VERSION ""

NS_ :

BS_:

BU_:

BO_ 3221225472 VECTOR__INDEPENDENT_SIG_MSG: 0 Vector__XXX
 SG_ Error_BMS_ID : 0|16@1+ (1,0) [0|0] "" Vector__XXX

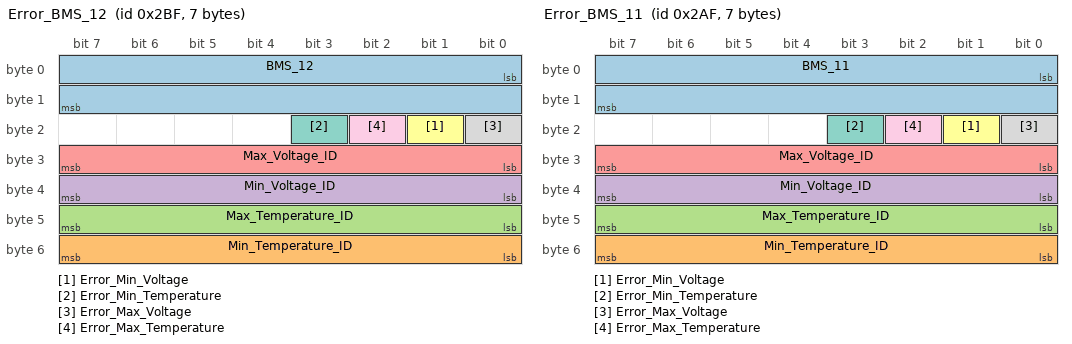
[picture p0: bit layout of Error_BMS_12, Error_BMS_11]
BO_ 703 Error_BMS_12: 7 Vector__XXX
 SG_ BMS_12 : 0|16@1- (1,0) [0|0] "" Vector__XXX
 SG_ Min_Temperature_ID : 48|8@1+ (1,0) [0|255] "" Vector__XXX
 SG_ Max_Temperature_ID : 40|8@1+ (1,0) [0|255] "" Vector__XXX
 SG_ Min_Voltage_ID : 32|8@1+ (1,0) [0|255] "" Vector__XXX
 SG_ Max_Voltage_ID : 24|8@1+ (1,0) [0|255] "" Vector__XXX
 SG_ Error_Min_Voltage : 17|1@1+ (1,0) [0|1] "" Vector__XXX
 SG_ Error_Min_Temperature : 19|1@1+ (1,0) [0|1] "" Vector__XXX
 SG_ Error_Max_Voltage : 16|1@1+ (1,0) [0|1] "" Vector__XXX
 SG_ Error_Max_Temperature : 18|1@1+ (1,0) [0|1] "" Vector__XXX

BO_ 687 Error_BMS_11: 7 Vector__XXX
 SG_ BMS_11 : 0|16@1- (1,0) [0|0] "" Vector__XXX
 SG_ Min_Temperature_ID : 48|8@1+ (1,0) [0|255] "" Vector__XXX
 SG_ Max_Temperature_ID : 40|8@1+ (1,0) [0|255] "" Vector__XXX
 SG_ Min_Voltage_ID : 32|8@1+ (1,0) [0|255] "" Vector__XXX
 SG_ Max_Voltage_ID : 24|8@1+ (1,0) [0|255] "" Vector__XXX
 SG_ Error_Min_Voltage : 17|1@1+ (1,0) [0|1] "" Vector__XXX
 SG_ Error_Min_Temperature : 19|1@1+ (1,0) [0|1] "" Vector__XXX
 SG_ Error_Max_Voltage : 16|1@1+ (1,0) [0|1] "" Vector__XXX
 SG_ Error_Max_Temperature : 18|1@1+ (1,0) [0|1] "" Vector__XXX

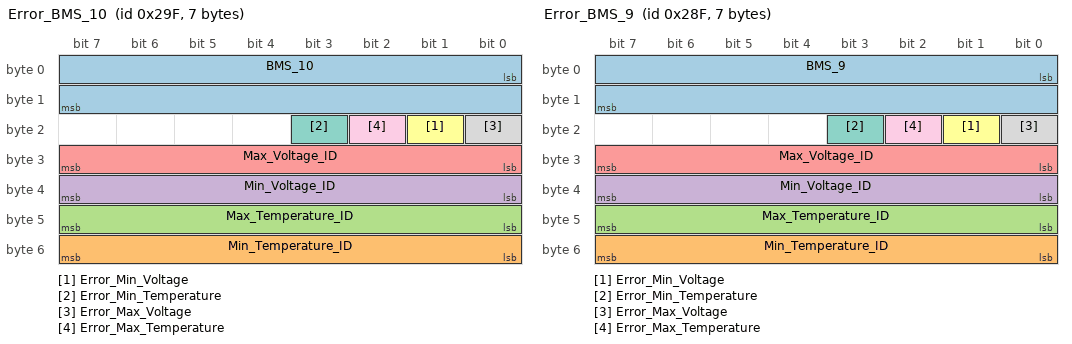
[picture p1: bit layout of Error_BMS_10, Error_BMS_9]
BO_ 671 Error_BMS_10: 7 Vector__XXX
 SG_ BMS_10 : 0|16@1- (1,0) [0|0] "" Vector__XXX
 SG_ Min_Temperature_ID : 48|8@1+ (1,0) [0|255] "" Vector__XXX
 SG_ Max_Temperature_ID : 40|8@1+ (1,0) [0|255] "" Vector__XXX
 SG_ Min_Voltage_ID : 32|8@1+ (1,0) [0|255] "" Vector__XXX
 SG_ Max_Voltage_ID : 24|8@1+ (1,0) [0|255] "" Vector__XXX
 SG_ Error_Min_Voltage : 17|1@1+ (1,0) [0|1] "" Vector__XXX
 SG_ Error_Min_Temperature : 19|1@1+ (1,0) [0|1] "" Vector__XXX
 SG_ Error_Max_Voltage : 16|1@1+ (1,0) [0|1] "" Vector__XXX
 SG_ Error_Max_Temperature : 18|1@1+ (1,0) [0|1] "" Vector__XXX

BO_ 655 Error_BMS_9: 7 Vector__XXX
 SG_ BMS_9 : 0|16@1- (1,0) [0|0] "" Vector__XXX
 SG_ Min_Temperature_ID : 48|8@1+ (1,0) [0|255] "" Vector__XXX
 SG_ Max_Temperature_ID : 40|8@1+ (1,0) [0|255] "" Vector__XXX
 SG_ Min_Voltage_ID : 32|8@1+ (1,0) [0|255] "" Vector__XXX
 SG_ Max_Voltage_ID : 24|8@1+ (1,0) [0|255] "" Vector__XXX
 SG_ Error_Min_Voltage : 17|1@1+ (1,0) [0|1] "" Vector__XXX
 SG_ Error_Min_Temperature : 19|1@1+ (1,0) [0|1] "" Vector__XXX
 SG_ Error_Max_Voltage : 16|1@1+ (1,0) [0|1] "" Vector__XXX
 SG_ Error_Max_Temperature : 18|1@1+ (1,0) [0|1] "" Vector__XXX

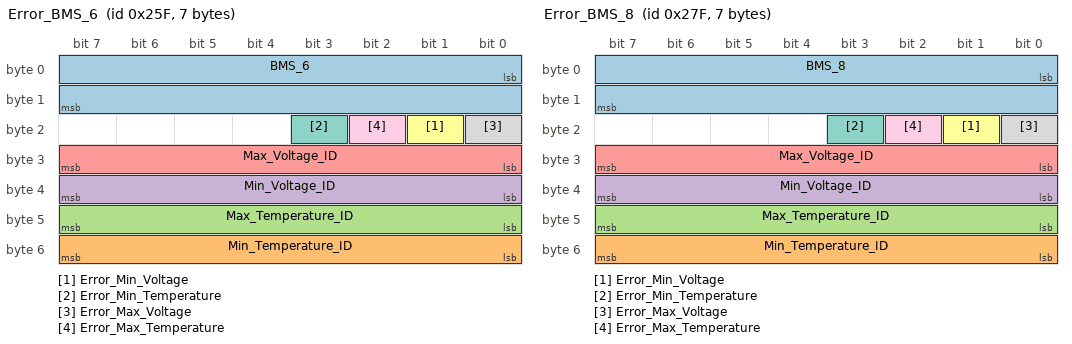
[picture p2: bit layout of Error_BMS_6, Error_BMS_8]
BO_ 607 Error_BMS_6: 7 Vector__XXX
 SG_ BMS_6 : 0|16@1- (1,0) [0|0] "" Vector__XXX
 SG_ Min_Temperature_ID : 48|8@1+ (1,0) [0|255] "" Vector__XXX
 SG_ Max_Temperature_ID : 40|8@1+ (1,0) [0|255] "" Vector__XXX
 SG_ Min_Voltage_ID : 32|8@1+ (1,0) [0|255] "" Vector__XXX
 SG_ Max_Voltage_ID : 24|8@1+ (1,0) [0|255] "" Vector__XXX
 SG_ Error_Min_Voltage : 17|1@1+ (1,0) [0|1] "" Vector__XXX
 SG_ Error_Min_Temperature : 19|1@1+ (1,0) [0|1] "" Vector__XXX
 SG_ Error_Max_Voltage : 16|1@1+ (1,0) [0|1] "" Vector__XXX
 SG_ Error_Max_Temperature : 18|1@1+ (1,0) [0|1] "" Vector__XXX

BO_ 639 Error_BMS_8: 7 Vector__XXX
 SG_ BMS_8 : 0|16@1- (1,0) [0|0] "" Vector__XXX
 SG_ Min_Temperature_ID : 48|8@1+ (1,0) [0|255] "" Vector__XXX
 SG_ Max_Temperature_ID : 40|8@1+ (1,0) [0|255] "" Vector__XXX
 SG_ Min_Voltage_ID : 32|8@1+ (1,0) [0|255] "" Vector__XXX
 SG_ Max_Voltage_ID : 24|8@1+ (1,0) [0|255] "" Vector__XXX
 SG_ Error_Min_Voltage : 17|1@1+ (1,0) [0|1] "" Vector__XXX
 SG_ Error_Min_Temperature : 19|1@1+ (1,0) [0|1] "" Vector__XXX
 SG_ Error_Max_Voltage : 16|1@1+ (1,0) [0|1] "" Vector__XXX
 SG_ Error_Max_Temperature : 18|1@1+ (1,0) [0|1] "" Vector__XXX

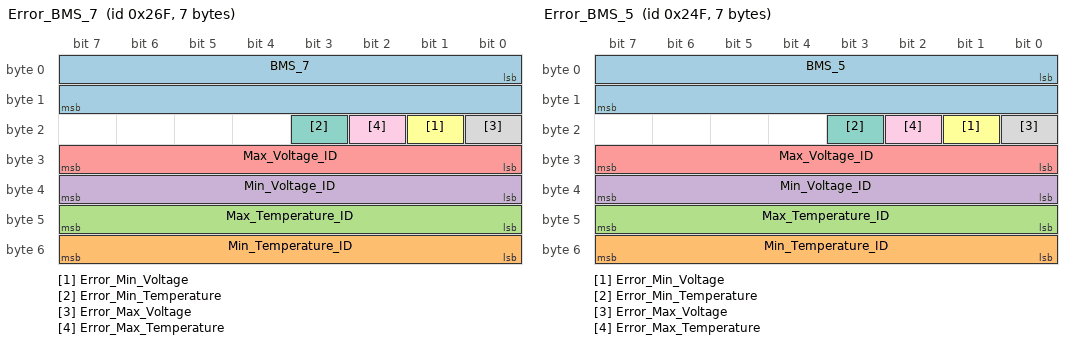
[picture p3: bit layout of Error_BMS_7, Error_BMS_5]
BO_ 623 Error_BMS_7: 7 Vector__XXX
 SG_ BMS_7 : 0|16@1- (1,0) [0|0] "" Vector__XXX
 SG_ Min_Temperature_ID : 48|8@1+ (1,0) [0|255] "" Vector__XXX
 SG_ Max_Temperature_ID : 40|8@1+ (1,0) [0|255] "" Vector__XXX
 SG_ Min_Voltage_ID : 32|8@1+ (1,0) [0|255] "" Vector__XXX
 SG_ Max_Voltage_ID : 24|8@1+ (1,0) [0|255] "" Vector__XXX
 SG_ Error_Min_Voltage : 17|1@1+ (1,0) [0|1] "" Vector__XXX
 SG_ Error_Min_Temperature : 19|1@1+ (1,0) [0|1] "" Vector__XXX
 SG_ Error_Max_Voltage : 16|1@1+ (1,0) [0|1] "" Vector__XXX
 SG_ Error_Max_Temperature : 18|1@1+ (1,0) [0|1] "" Vector__XXX

BO_ 591 Error_BMS_5: 7 Vector__XXX
 SG_ BMS_5 : 0|16@1- (1,0) [0|0] "" Vector__XXX
 SG_ Min_Temperature_ID : 48|8@1+ (1,0) [0|255] "" Vector__XXX
 SG_ Max_Temperature_ID : 40|8@1+ (1,0) [0|255] "" Vector__XXX
 SG_ Min_Voltage_ID : 32|8@1+ (1,0) [0|255] "" Vector__XXX
 SG_ Max_Voltage_ID : 24|8@1+ (1,0) [0|255] "" Vector__XXX
 SG_ Error_Min_Voltage : 17|1@1+ (1,0) [0|1] "" Vector__XXX
 SG_ Error_Min_Temperature : 19|1@1+ (1,0) [0|1] "" Vector__XXX
 SG_ Error_Max_Voltage : 16|1@1+ (1,0) [0|1] "" Vector__XXX
 SG_ Error_Max_Temperature : 18|1@1+ (1,0) [0|1] "" Vector__XXX

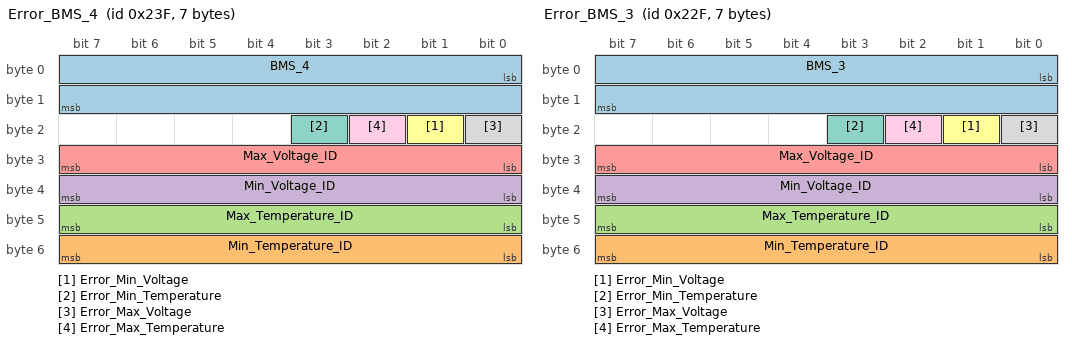
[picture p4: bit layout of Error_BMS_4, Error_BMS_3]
BO_ 575 Error_BMS_4: 7 Vector__XXX
 SG_ BMS_4 : 0|16@1- (1,0) [0|0] "" Vector__XXX
 SG_ Min_Temperature_ID : 48|8@1+ (1,0) [0|255] "" Vector__XXX
 SG_ Max_Temperature_ID : 40|8@1+ (1,0) [0|255] "" Vector__XXX
 SG_ Min_Voltage_ID : 32|8@1+ (1,0) [0|255] "" Vector__XXX
 SG_ Max_Voltage_ID : 24|8@1+ (1,0) [0|255] "" Vector__XXX
 SG_ Error_Min_Voltage : 17|1@1+ (1,0) [0|1] "" Vector__XXX
 SG_ Error_Min_Temperature : 19|1@1+ (1,0) [0|1] "" Vector__XXX
 SG_ Error_Max_Voltage : 16|1@1+ (1,0) [0|1] "" Vector__XXX
 SG_ Error_Max_Temperature : 18|1@1+ (1,0) [0|1] "" Vector__XXX

BO_ 559 Error_BMS_3: 7 Vector__XXX
 SG_ BMS_3 : 0|16@1- (1,0) [0|0] "" Vector__XXX
 SG_ Min_Temperature_ID : 48|8@1+ (1,0) [0|255] "" Vector__XXX
 SG_ Max_Temperature_ID : 40|8@1+ (1,0) [0|255] "" Vector__XXX
 SG_ Min_Voltage_ID : 32|8@1+ (1,0) [0|255] "" Vector__XXX
 SG_ Max_Voltage_ID : 24|8@1+ (1,0) [0|255] "" Vector__XXX
 SG_ Error_Min_Voltage : 17|1@1+ (1,0) [0|1] "" Vector__XXX
 SG_ Error_Min_Temperature : 19|1@1+ (1,0) [0|1] "" Vector__XXX
 SG_ Error_Max_Voltage : 16|1@1+ (1,0) [0|1] "" Vector__XXX
 SG_ Error_Max_Temperature : 18|1@1+ (1,0) [0|1] "" Vector__XXX

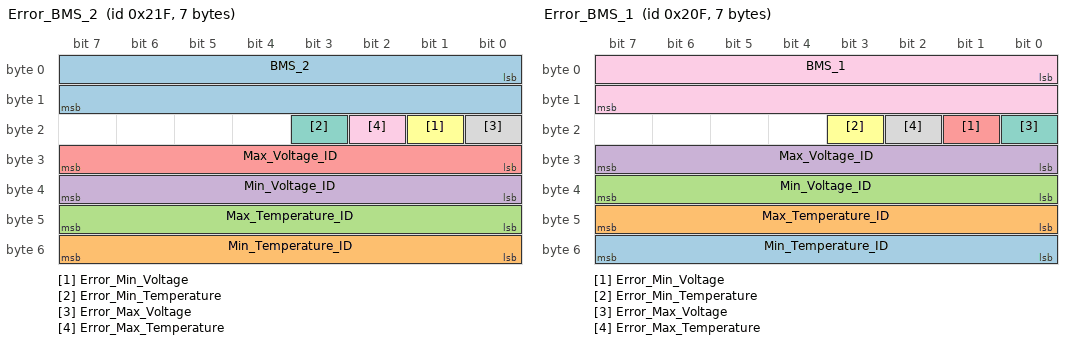
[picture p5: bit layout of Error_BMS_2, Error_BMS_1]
BO_ 543 Error_BMS_2: 7 Vector__XXX
 SG_ BMS_2 : 0|16@1- (1,0) [0|0] "" Vector__XXX
 SG_ Min_Temperature_ID : 48|8@1+ (1,0) [0|255] "" Vector__XXX
 SG_ Max_Temperature_ID : 40|8@1+ (1,0) [0|255] "" Vector__XXX
 SG_ Min_Voltage_ID : 32|8@1+ (1,0) [0|255] "" Vector__XXX
 SG_ Max_Voltage_ID : 24|8@1+ (1,0) [0|255] "" Vector__XXX
 SG_ Error_Min_Voltage : 17|1@1+ (1,0) [0|1] "" Vector__XXX
 SG_ Error_Min_Temperature : 19|1@1+ (1,0) [0|1] "" Vector__XXX
 SG_ Error_Max_Voltage : 16|1@1+ (1,0) [0|1] "" Vector__XXX
 SG_ Error_Max_Temperature : 18|1@1+ (1,0) [0|1] "" Vector__XXX

BO_ 527 Error_BMS_1: 7 Vector__XXX
 SG_ Min_Temperature_ID : 48|8@1+ (1,0) [0|255] "" Vector__XXX
 SG_ Max_Temperature_ID : 40|8@1+ (1,0) [0|255] "" Vector__XXX
 SG_ Min_Voltage_ID : 32|8@1+ (1,0) [0|255] "" Vector__XXX
 SG_ Max_Voltage_ID : 24|8@1+ (1,0) [0|255] "" Vector__XXX
 SG_ Error_Min_Voltage : 17|1@1+ (1,0) [0|1] "" Vector__XXX
 SG_ Error_Min_Temperature : 19|1@1+ (1,0) [0|1] "" Vector__XXX
 SG_ Error_Max_Voltage : 16|1@1+ (1,0) [0|1] "" Vector__XXX
 SG_ Error_Max_Temperature : 18|1@1+ (1,0) [0|1] "" Vector__XXX
 SG_ BMS_1 : 0|16@1- (1,0) [0|0] "" Vector__XXX

BO_ 256 Set_Min_Max_Voltage_Temp: 6 Vector__XXX
 SG_ Value_Min_Allowed_Voltage : 16|16@1+ (0.0001,0) [0|0] "V" Vector__XXX
 SG_ Value_Max_Allowed_Voltage : 0|16@1+ (0.0001,0) [0|0] "V" Vector__XXX
 SG_ Value_Max_Allowed_Temperature : 32|16@1- (0.01,0) [-327.68|327.67] "°C" Vector__XXX

BO_ 434 RX_BMS_12_Voltage_05_08: 0 Vector__XXX

BO_ 433 RX_BMS_12_Voltage_01_04: 0 Vector__XXX

BO_ 440 RX_BMS_12_Temp_05_REF: 0 Vector__XXX

BO_ 439 RX_BMS_12_Temp_01_04: 0 Vector__XXX

BO_ 438 RX_BMS_12_Extrem_Voltages: 0 Vector__XXX

BO_ 445 RX_BMS_12_Extrem_Temp: 0 Vector__XXX

BO_ 418 RX_BMS_11_Voltage_05_08: 0 Vector__XXX

BO_ 417 RX_BMS_11_Voltage_01_04: 0 Vector__XXX

BO_ 424 RX_BMS_11_Temp_05_REF: 0 Vector__XXX

BO_ 423 RX_BMS_11_Temp_01_04: 0 Vector__XXX

BO_ 422 RX_BMS_11_Extrem_Voltages: 0 Vector__XXX

BO_ 429 RX_BMS_11_Extrem_Temp: 0 Vector__XXX

BO_ 402 RX_BMS_10_Voltage_05_08: 0 Vector__XXX

BO_ 401 RX_BMS_10_Voltage_01_04: 0 Vector__XXX

BO_ 408 RX_BMS_10_Temp_05_REF: 0 Vector__XXX

BO_ 407 RX_BMS_10_Temp_01_04: 0 Vector__XXX

BO_ 406 RX_BMS_10_Extrem_Voltages: 0 Vector__XXX

BO_ 413 RX_BMS_10_Extrem_Temp: 0 Vector__XXX

BO_ 386 RX_BMS_9_Voltage_05_08: 0 Vector__XXX

BO_ 385 RX_BMS_9_Voltage_01_04: 0 Vector__XXX

BO_ 392 RX_BMS_9_Temp_05_REF: 0 Vector__XXX

BO_ 391 RX_BMS_9_Temp_01_04: 0 Vector__XXX

BO_ 390 RX_BMS_9_Extrem_Voltages: 0 Vector__XXX

BO_ 397 RX_BMS_9_Extrem_Temp: 0 Vector__XXX

BO_ 370 RX_BMS_8_Voltage_05_08: 0 Vector__XXX

BO_ 369 RX_BMS_8_Voltage_01_04: 0 Vector__XXX

BO_ 376 RX_BMS_8_Temp_05_REF: 0 Vector__XXX

BO_ 375 RX_BMS_8_Temp_01_04: 0 Vector__XXX

BO_ 374 RX_BMS_8_Extrem_Voltages: 0 Vector__XXX

BO_ 381 RX_BMS_8_Extrem_Temp: 0 Vector__XXX

BO_ 354 RX_BMS_7_Voltage_05_08: 0 Vector__XXX

BO_ 353 RX_BMS_7_Voltage_01_04: 0 Vector__XXX

BO_ 360 RX_BMS_7_Temp_05_REF: 0 Vector__XXX

BO_ 359 RX_BMS_7_Temp_01_04: 0 Vector__XXX

BO_ 358 RX_BMS_7_Extrem_Voltages: 0 Vector__XXX

BO_ 365 RX_BMS_7_Extrem_Temp: 0 Vector__XXX

BO_ 338 RX_BMS_6_Voltage_05_08: 0 Vector__XXX

BO_ 337 RX_BMS_6_Voltage_01_04: 0 Vector__XXX

BO_ 344 RX_BMS_6_Temp_05_REF: 0 Vector__XXX

BO_ 343 RX_BMS_6_Temp_01_04: 0 Vector__XXX

BO_ 342 RX_BMS_6_Extrem_Voltages: 0 Vector__XXX

BO_ 349 RX_BMS_6_Extrem_Temp: 0 Vector__XXX

BO_ 322 RX_BMS_5_Voltage_05_08: 0 Vector__XXX

BO_ 321 RX_BMS_5_Voltage_01_04: 0 Vector__XXX

BO_ 328 RX_BMS_5_Temp_05_REF: 0 Vector__XXX

BO_ 327 RX_BMS_5_Temp_01_04: 0 Vector__XXX

BO_ 326 RX_BMS_5_Extrem_Voltages: 0 Vector__XXX

BO_ 333 RX_BMS_5_Extrem_Temp: 0 Vector__XXX

BO_ 306 RX_BMS_4_Voltage_05_08: 0 Vector__XXX

BO_ 305 RX_BMS_4_Voltage_01_04: 0 Vector__XXX

BO_ 312 RX_BMS_4_Temp_05_REF: 0 Vector__XXX

BO_ 311 RX_BMS_4_Temp_01_04: 0 Vector__XXX

BO_ 310 RX_BMS_4_Extrem_Voltages: 0 Vector__XXX

BO_ 317 RX_BMS_4_Extrem_Temp: 0 Vector__XXX

BO_ 290 RX_BMS_3_Voltage_05_08: 0 Vector__XXX

BO_ 289 RX_BMS_3_Voltage_01_04: 0 Vector__XXX

BO_ 296 RX_BMS_3_Temp_05_REF: 0 Vector__XXX

BO_ 295 RX_BMS_3_Temp_01_04: 0 Vector__XXX

BO_ 294 RX_BMS_3_Extrem_Voltages: 0 Vector__XXX

BO_ 301 RX_BMS_3_Extrem_Temp: 0 Vector__XXX

BO_ 274 RX_BMS_2_Voltage_05_08: 0 Vector__XXX

BO_ 273 RX_BMS_2_Voltage_01_04: 0 Vector__XXX

BO_ 280 RX_BMS_2_Temp_05_REF: 0 Vector__XXX

BO_ 279 RX_BMS_2_Temp_01_04: 0 Vector__XXX

BO_ 278 RX_BMS_2_Extrem_Voltages: 0 Vector__XXX

BO_ 285 RX_BMS_2_Extrem_Temp: 0 Vector__XXX

BO_ 258 RX_BMS_1_Voltage_05_REF: 0 Vector__XXX

BO_ 257 RX_BMS_1_Voltage_01_04: 0 Vector__XXX

BO_ 264 RX_BMS_1_Temp_05_REF: 0 Vector__XXX

BO_ 263 RX_BMS_1_Temp_01_04: 0 Vector__XXX

BO_ 262 RX_BMS_1_Extrem_Voltages: 0 Vector__XXX

BO_ 269 RX_BMS_1_Extrem_Temp: 0 Vector__XXX

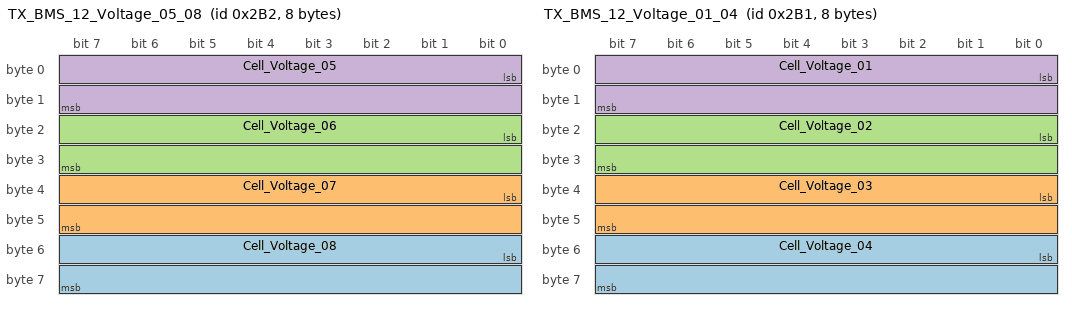
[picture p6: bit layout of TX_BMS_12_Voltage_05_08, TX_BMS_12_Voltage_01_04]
BO_ 690 TX_BMS_12_Voltage_05_08: 8 Vector__XXX
 SG_ Cell_Voltage_08 : 48|16@1+ (0.0001,0) [0|6.5535] "V" Vector__XXX
 SG_ Cell_Voltage_07 : 32|16@1+ (0.0001,0) [0|6.5535] "V" Vector__XXX
 SG_ Cell_Voltage_06 : 16|16@1+ (0.0001,0) [0|6.5535] "V" Vector__XXX
 SG_ Cell_Voltage_05 : 0|16@1+ (0.0001,0) [0|6.5535] "V" Vector__XXX

BO_ 689 TX_BMS_12_Voltage_01_04: 8 Vector__XXX
 SG_ Cell_Voltage_04 : 48|16@1+ (0.0001,0) [0|6.5535] "V" Vector__XXX
 SG_ Cell_Voltage_03 : 32|16@1+ (0.0001,0) [0|6.5535] "V" Vector__XXX
 SG_ Cell_Voltage_02 : 16|16@1+ (0.0001,0) [0|6.5535] "V" Vector__XXX
 SG_ Cell_Voltage_01 : 0|16@1+ (0.0001,0) [0|6.5535] "V" Vector__XXX

BO_ 696 TX_BMS_12_Temp_05_REF: 4 Vector__XXX
 SG_ Ref_Voltage : 16|16@1- (1,0) [0|0] "V" Vector__XXX
 SG_ Cell_Temperature_05 : 0|16@1- (0.01,0) [-327.68|327.67] "°C" Vector__XXX

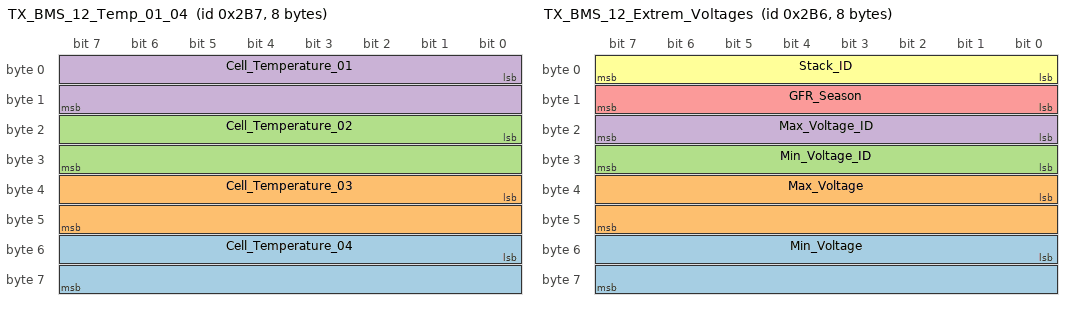
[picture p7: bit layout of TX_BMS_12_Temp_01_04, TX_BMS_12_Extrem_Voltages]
BO_ 695 TX_BMS_12_Temp_01_04: 8 Vector__XXX
 SG_ Cell_Temperature_04 : 48|16@1- (0.01,0) [-327.68|327.67] "°C" Vector__XXX
 SG_ Cell_Temperature_03 : 32|16@1- (0.01,0) [-327.68|327.67] "°C" Vector__XXX
 SG_ Cell_Temperature_02 : 16|16@1- (0.01,0) [-327.68|327.67] "°C" Vector__XXX
 SG_ Cell_Temperature_01 : 0|16@1- (0.01,0) [-327.68|327.67] "°C" Vector__XXX

BO_ 694 TX_BMS_12_Extrem_Voltages: 8 Vector__XXX
 SG_ Min_Voltage : 48|16@1+ (0.0001,0) [0|6.5535] "V" Vector__XXX
 SG_ Max_Voltage : 32|16@1+ (0.0001,0) [0|6.5535] "V" Vector__XXX
 SG_ Min_Voltage_ID : 24|8@1+ (1,0) [0|255] "" Vector__XXX
 SG_ Max_Voltage_ID : 16|8@1+ (1,0) [0|255] "" Vector__XXX
 SG_ GFR_Season : 8|8@1+ (1,0) [0|255] "" Vector__XXX
 SG_ Stack_ID : 0|8@1+ (1,0) [0|255] "" Vector__XXX

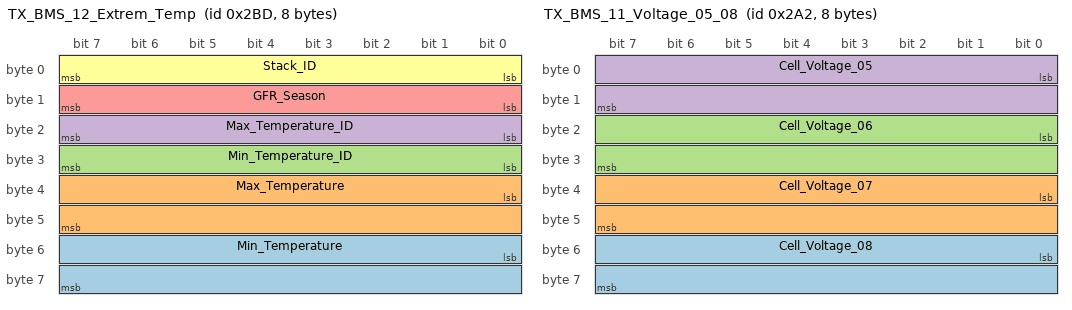
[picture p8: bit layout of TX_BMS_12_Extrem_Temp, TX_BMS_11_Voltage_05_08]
BO_ 701 TX_BMS_12_Extrem_Temp: 8 Vector__XXX
 SG_ Min_Temperature : 48|16@1- (0.01,0) [-327.68|327.67] "°C" Vector__XXX
 SG_ Max_Temperature : 32|16@1- (0.01,0) [-327.68|327.67] "°C" Vector__XXX
 SG_ Min_Temperature_ID : 24|8@1+ (1,0) [0|255] "" Vector__XXX
 SG_ Max_Temperature_ID : 16|8@1+ (1,0) [0|255] "" Vector__XXX
 SG_ GFR_Season : 8|8@1+ (1,0) [0|255] "" Vector__XXX
 SG_ Stack_ID : 0|8@1+ (1,0) [0|255] "" Vector__XXX

BO_ 674 TX_BMS_11_Voltage_05_08: 8 Vector__XXX
 SG_ Cell_Voltage_08 : 48|16@1+ (0.0001,0) [0|6.5535] "V" Vector__XXX
 SG_ Cell_Voltage_07 : 32|16@1+ (0.0001,0) [0|6.5535] "V" Vector__XXX
 SG_ Cell_Voltage_06 : 16|16@1+ (0.0001,0) [0|6.5535] "V" Vector__XXX
 SG_ Cell_Voltage_05 : 0|16@1+ (0.0001,0) [0|6.5535] "V" Vector__XXX

BO_ 673 TX_BMS_11_Voltage_01_04: 8 Vector__XXX
 SG_ Cell_Voltage_04 : 48|16@1+ (0.0001,0) [0|6.5535] "V" Vector__XXX
 SG_ Cell_Voltage_03 : 32|16@1+ (0.0001,0) [0|6.5535] "V" Vector__XXX
 SG_ Cell_Voltage_02 : 16|16@1+ (0.0001,0) [0|6.5535] "V" Vector__XXX
 SG_ Cell_Voltage_01 : 0|16@1+ (0.0001,0) [0|6.5535] "V" Vector__XXX

BO_ 680 TX_BMS_11_Temp_05_REF: 4 Vector__XXX
 SG_ Ref_Voltage : 16|16@1- (1,0) [0|0] "V" Vector__XXX
 SG_ Cell_Temperature_05 : 0|16@1- (0.01,0) [-327.68|327.67] "°C" Vector__XXX

BO_ 679 TX_BMS_11_Temp_01_04: 8 Vector__XXX
 SG_ Cell_Temperature_04 : 48|16@1- (0.01,0) [-327.68|327.67] "°C" Vector__XXX
 SG_ Cell_Temperature_03 : 32|16@1- (0.01,0) [-327.68|327.67] "°C" Vector__XXX
 SG_ Cell_Temperature_02 : 16|16@1- (0.01,0) [-327.68|327.67] "°C" Vector__XXX
 SG_ Cell_Temperature_01 : 0|16@1- (0.01,0) [-327.68|327.67] "°C" Vector__XXX

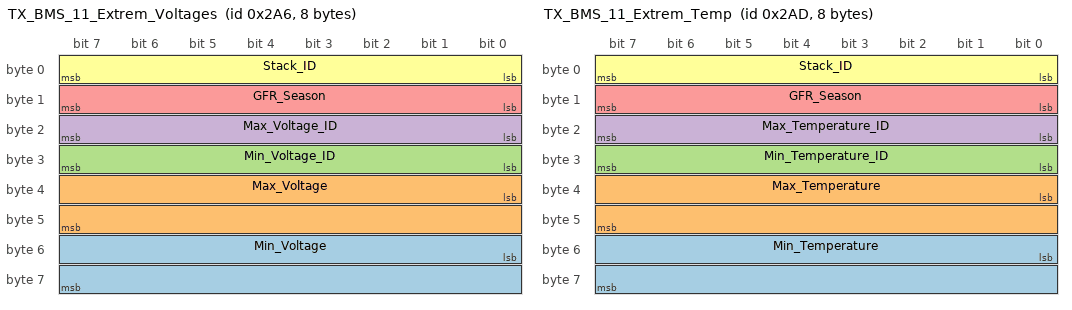
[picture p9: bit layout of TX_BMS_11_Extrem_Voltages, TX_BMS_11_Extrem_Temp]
BO_ 678 TX_BMS_11_Extrem_Voltages: 8 Vector__XXX
 SG_ Min_Voltage : 48|16@1+ (0.0001,0) [0|6.5535] "V" Vector__XXX
 SG_ Max_Voltage : 32|16@1+ (0.0001,0) [0|6.5535] "V" Vector__XXX
 SG_ Min_Voltage_ID : 24|8@1+ (1,0) [0|255] "" Vector__XXX
 SG_ Max_Voltage_ID : 16|8@1+ (1,0) [0|255] "" Vector__XXX
 SG_ GFR_Season : 8|8@1+ (1,0) [0|255] "" Vector__XXX
 SG_ Stack_ID : 0|8@1+ (1,0) [0|255] "" Vector__XXX

BO_ 685 TX_BMS_11_Extrem_Temp: 8 Vector__XXX
 SG_ Min_Temperature : 48|16@1- (0.01,0) [-327.68|327.67] "°C" Vector__XXX
 SG_ Max_Temperature : 32|16@1- (0.01,0) [-327.68|327.67] "°C" Vector__XXX
 SG_ Min_Temperature_ID : 24|8@1+ (1,0) [0|255] "" Vector__XXX
 SG_ Max_Temperature_ID : 16|8@1+ (1,0) [0|255] "" Vector__XXX
 SG_ GFR_Season : 8|8@1+ (1,0) [0|255] "" Vector__XXX
 SG_ Stack_ID : 0|8@1+ (1,0) [0|255] "" Vector__XXX

BO_ 658 TX_BMS_10_Voltage_05_08: 8 Vector__XXX
 SG_ Cell_Voltage_08 : 48|16@1+ (0.0001,0) [0|6.5535] "V" Vector__XXX
 SG_ Cell_Voltage_07 : 32|16@1+ (0.0001,0) [0|6.5535] "V" Vector__XXX
 SG_ Cell_Voltage_06 : 16|16@1+ (0.0001,0) [0|6.5535] "V" Vector__XXX
 SG_ Cell_Voltage_05 : 0|16@1+ (0.0001,0) [0|6.5535] "V" Vector__XXX

BO_ 657 TX_BMS_10_Voltage_01_04: 8 Vector__XXX
 SG_ Cell_Voltage_04 : 48|16@1+ (0.0001,0) [0|6.5535] "V" Vector__XXX
 SG_ Cell_Voltage_03 : 32|16@1+ (0.0001,0) [0|6.5535] "V" Vector__XXX
 SG_ Cell_Voltage_02 : 16|16@1+ (0.0001,0) [0|6.5535] "V" Vector__XXX
 SG_ Cell_Voltage_01 : 0|16@1+ (0.0001,0) [0|6.5535] "V" Vector__XXX

BO_ 664 TX_BMS_10_Temp_05_REF: 4 Vector__XXX
 SG_ Ref_Voltage : 16|16@1- (1,0) [0|0] "V" Vector__XXX
 SG_ Cell_Temperature_05 : 0|16@1- (0.01,0) [-327.68|327.67] "°C" Vector__XXX

BO_ 663 TX_BMS_10_Temp_01_04: 8 Vector__XXX
 SG_ Cell_Temperature_04 : 48|16@1- (0.01,0) [-327.68|327.67] "°C" Vector__XXX
 SG_ Cell_Temperature_03 : 32|16@1- (0.01,0) [-327.68|327.67] "°C" Vector__XXX
 SG_ Cell_Temperature_02 : 16|16@1- (0.01,0) [-327.68|327.67] "°C" Vector__XXX
 SG_ Cell_Temperature_01 : 0|16@1- (0.01,0) [-327.68|327.67] "°C" Vector__XXX

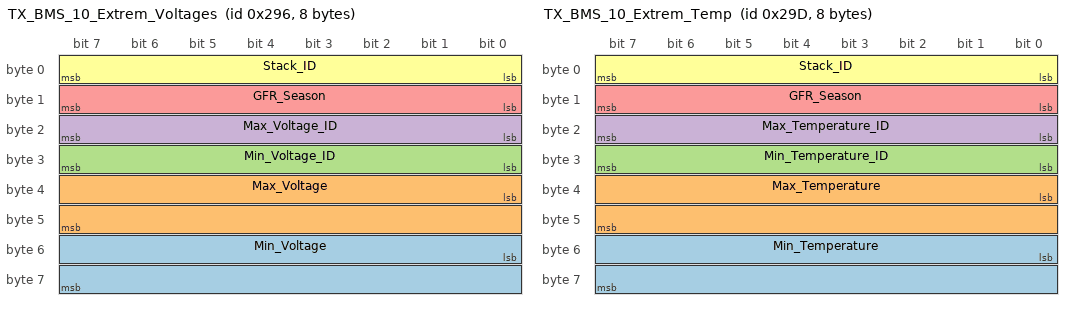
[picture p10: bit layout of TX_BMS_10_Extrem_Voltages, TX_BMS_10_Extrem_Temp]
BO_ 662 TX_BMS_10_Extrem_Voltages: 8 Vector__XXX
 SG_ Min_Voltage : 48|16@1+ (0.0001,0) [0|6.5535] "V" Vector__XXX
 SG_ Max_Voltage : 32|16@1+ (0.0001,0) [0|6.5535] "V" Vector__XXX
 SG_ Min_Voltage_ID : 24|8@1+ (1,0) [0|255] "" Vector__XXX
 SG_ Max_Voltage_ID : 16|8@1+ (1,0) [0|255] "" Vector__XXX
 SG_ GFR_Season : 8|8@1+ (1,0) [0|255] "" Vector__XXX
 SG_ Stack_ID : 0|8@1+ (1,0) [0|255] "" Vector__XXX

BO_ 669 TX_BMS_10_Extrem_Temp: 8 Vector__XXX
 SG_ Min_Temperature : 48|16@1- (0.01,0) [-327.68|327.67] "°C" Vector__XXX
 SG_ Max_Temperature : 32|16@1- (0.01,0) [-327.68|327.67] "°C" Vector__XXX
 SG_ Min_Temperature_ID : 24|8@1+ (1,0) [0|255] "" Vector__XXX
 SG_ Max_Temperature_ID : 16|8@1+ (1,0) [0|255] "" Vector__XXX
 SG_ GFR_Season : 8|8@1+ (1,0) [0|255] "" Vector__XXX
 SG_ Stack_ID : 0|8@1+ (1,0) [0|255] "" Vector__XXX

BO_ 642 TX_BMS_9_Voltage_05_08: 8 Vector__XXX
 SG_ Cell_Voltage_08 : 48|16@1+ (0.0001,0) [0|6.5535] "V" Vector__XXX
 SG_ Cell_Voltage_07 : 32|16@1+ (0.0001,0) [0|6.5535] "V" Vector__XXX
 SG_ Cell_Voltage_06 : 16|16@1+ (0.0001,0) [0|6.5535] "V" Vector__XXX
 SG_ Cell_Voltage_05 : 0|16@1+ (0.0001,0) [0|6.5535] "V" Vector__XXX

BO_ 641 TX_BMS_9_Voltage_01_04: 8 Vector__XXX
 SG_ Cell_Voltage_04 : 48|16@1+ (0.0001,0) [0|6.5535] "V" Vector__XXX
 SG_ Cell_Voltage_03 : 32|16@1+ (0.0001,0) [0|6.5535] "V" Vector__XXX
 SG_ Cell_Voltage_02 : 16|16@1+ (0.0001,0) [0|6.5535] "V" Vector__XXX
 SG_ Cell_Voltage_01 : 0|16@1+ (0.0001,0) [0|6.5535] "V" Vector__XXX

BO_ 648 TX_BMS_9_Temp_05_REF: 4 Vector__XXX
 SG_ Ref_Voltage : 16|16@1- (1,0) [0|0] "V" Vector__XXX
 SG_ Cell_Temperature_05 : 0|16@1- (0.01,0) [-327.68|327.67] "°C" Vector__XXX

BO_ 647 TX_BMS_9_Temp_01_04: 8 Vector__XXX
 SG_ Cell_Temperature_04 : 48|16@1- (0.01,0) [-327.68|327.67] "°C" Vector__XXX
 SG_ Cell_Temperature_03 : 32|16@1- (0.01,0) [-327.68|327.67] "°C" Vector__XXX
 SG_ Cell_Temperature_02 : 16|16@1- (0.01,0) [-327.68|327.67] "°C" Vector__XXX
 SG_ Cell_Temperature_01 : 0|16@1- (0.01,0) [-327.68|327.67] "°C" Vector__XXX

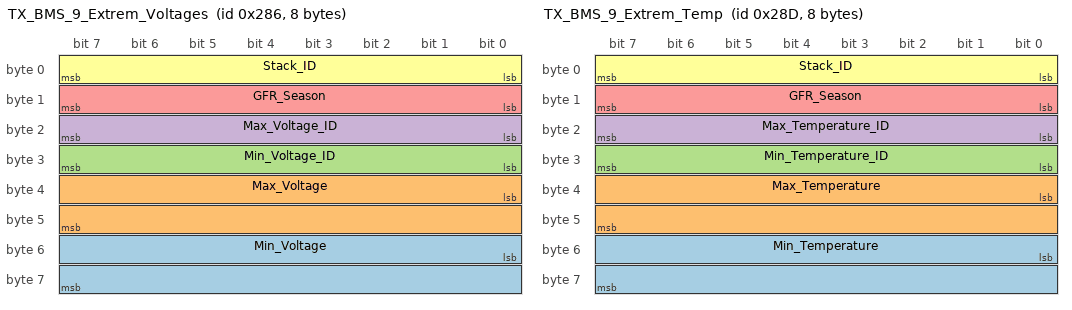
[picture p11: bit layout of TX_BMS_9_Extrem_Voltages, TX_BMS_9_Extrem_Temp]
BO_ 646 TX_BMS_9_Extrem_Voltages: 8 Vector__XXX
 SG_ Min_Voltage : 48|16@1+ (0.0001,0) [0|6.5535] "V" Vector__XXX
 SG_ Max_Voltage : 32|16@1+ (0.0001,0) [0|6.5535] "V" Vector__XXX
 SG_ Min_Voltage_ID : 24|8@1+ (1,0) [0|255] "" Vector__XXX
 SG_ Max_Voltage_ID : 16|8@1+ (1,0) [0|255] "" Vector__XXX
 SG_ GFR_Season : 8|8@1+ (1,0) [0|255] "" Vector__XXX
 SG_ Stack_ID : 0|8@1+ (1,0) [0|255] "" Vector__XXX

BO_ 653 TX_BMS_9_Extrem_Temp: 8 Vector__XXX
 SG_ Min_Temperature : 48|16@1- (0.01,0) [-327.68|327.67] "°C" Vector__XXX
 SG_ Max_Temperature : 32|16@1- (0.01,0) [-327.68|327.67] "°C" Vector__XXX
 SG_ Min_Temperature_ID : 24|8@1+ (1,0) [0|255] "" Vector__XXX
 SG_ Max_Temperature_ID : 16|8@1+ (1,0) [0|255] "" Vector__XXX
 SG_ GFR_Season : 8|8@1+ (1,0) [0|255] "" Vector__XXX
 SG_ Stack_ID : 0|8@1+ (1,0) [0|255] "" Vector__XXX

BO_ 626 TX_BMS_8_Voltage_05_08: 8 Vector__XXX
 SG_ Cell_Voltage_08 : 48|16@1+ (0.0001,0) [0|6.5535] "V" Vector__XXX
 SG_ Cell_Voltage_07 : 32|16@1+ (0.0001,0) [0|6.5535] "V" Vector__XXX
 SG_ Cell_Voltage_06 : 16|16@1+ (0.0001,0) [0|6.5535] "V" Vector__XXX
 SG_ Cell_Voltage_05 : 0|16@1+ (0.0001,0) [0|6.5535] "V" Vector__XXX

BO_ 625 TX_BMS_8_Voltage_01_04: 8 Vector__XXX
 SG_ Cell_Voltage_04 : 48|16@1+ (0.0001,0) [0|6.5535] "V" Vector__XXX
 SG_ Cell_Voltage_03 : 32|16@1+ (0.0001,0) [0|6.5535] "V" Vector__XXX
 SG_ Cell_Voltage_02 : 16|16@1+ (0.0001,0) [0|6.5535] "V" Vector__XXX
 SG_ Cell_Voltage_01 : 0|16@1+ (0.0001,0) [0|6.5535] "V" Vector__XXX

BO_ 632 TX_BMS_8_Temp_05_REF: 4 Vector__XXX
 SG_ Ref_Voltage : 16|16@1- (1,0) [0|0] "V" Vector__XXX
 SG_ Cell_Temperature_05 : 0|16@1- (0.01,0) [-327.68|327.67] "°C" Vector__XXX

BO_ 631 TX_BMS_8_Temp_01_04: 8 Vector__XXX
 SG_ Cell_Temperature_04 : 48|16@1- (0.01,0) [-327.68|327.67] "°C" Vector__XXX
 SG_ Cell_Temperature_03 : 32|16@1- (0.01,0) [-327.68|327.67] "°C" Vector__XXX
 SG_ Cell_Temperature_02 : 16|16@1- (0.01,0) [-327.68|327.67] "°C" Vector__XXX
 SG_ Cell_Temperature_01 : 0|16@1- (0.01,0) [-327.68|327.67] "°C" Vector__XXX

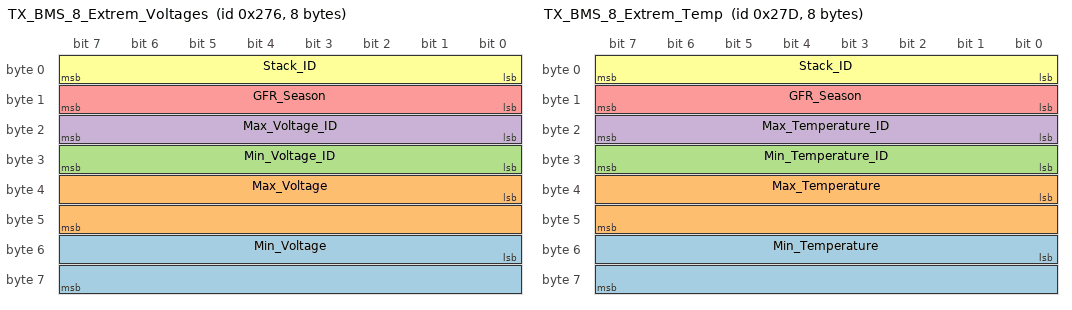
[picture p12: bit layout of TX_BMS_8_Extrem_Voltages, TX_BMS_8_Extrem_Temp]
BO_ 630 TX_BMS_8_Extrem_Voltages: 8 Vector__XXX
 SG_ Min_Voltage : 48|16@1+ (0.0001,0) [0|6.5535] "V" Vector__XXX
 SG_ Max_Voltage : 32|16@1+ (0.0001,0) [0|6.5535] "V" Vector__XXX
 SG_ Min_Voltage_ID : 24|8@1+ (1,0) [0|255] "" Vector__XXX
 SG_ Max_Voltage_ID : 16|8@1+ (1,0) [0|255] "" Vector__XXX
 SG_ GFR_Season : 8|8@1+ (1,0) [0|255] "" Vector__XXX
 SG_ Stack_ID : 0|8@1+ (1,0) [0|255] "" Vector__XXX

BO_ 637 TX_BMS_8_Extrem_Temp: 8 Vector__XXX
 SG_ Min_Temperature : 48|16@1- (0.01,0) [-327.68|327.67] "°C" Vector__XXX
 SG_ Max_Temperature : 32|16@1- (0.01,0) [-327.68|327.67] "°C" Vector__XXX
 SG_ Min_Temperature_ID : 24|8@1+ (1,0) [0|255] "" Vector__XXX
 SG_ Max_Temperature_ID : 16|8@1+ (1,0) [0|255] "" Vector__XXX
 SG_ GFR_Season : 8|8@1+ (1,0) [0|255] "" Vector__XXX
 SG_ Stack_ID : 0|8@1+ (1,0) [0|255] "" Vector__XXX

BO_ 610 TX_BMS_7_Voltage_05_08: 8 Vector__XXX
 SG_ Cell_Voltage_08 : 48|16@1+ (0.0001,0) [0|6.5535] "V" Vector__XXX
 SG_ Cell_Voltage_07 : 32|16@1+ (0.0001,0) [0|6.5535] "V" Vector__XXX
 SG_ Cell_Voltage_06 : 16|16@1+ (0.0001,0) [0|6.5535] "V" Vector__XXX
 SG_ Cell_Voltage_05 : 0|16@1+ (0.0001,0) [0|6.5535] "V" Vector__XXX

BO_ 609 TX_BMS_7_Voltage_01_04: 8 Vector__XXX
 SG_ Cell_Voltage_04 : 48|16@1+ (0.0001,0) [0|6.5535] "V" Vector__XXX
 SG_ Cell_Voltage_03 : 32|16@1+ (0.0001,0) [0|6.5535] "V" Vector__XXX
 SG_ Cell_Voltage_02 : 16|16@1+ (0.0001,0) [0|6.5535] "V" Vector__XXX
 SG_ Cell_Voltage_01 : 0|16@1+ (0.0001,0) [0|6.5535] "V" Vector__XXX

BO_ 616 TX_BMS_7_Temp_05_REF: 4 Vector__XXX
 SG_ Ref_Voltage : 16|16@1- (1,0) [0|0] "V" Vector__XXX
 SG_ Cell_Temperature_05 : 0|16@1- (0.01,0) [-327.68|327.67] "°C" Vector__XXX

BO_ 615 TX_BMS_7_Temp_01_04: 8 Vector__XXX
 SG_ Cell_Temperature_04 : 48|16@1- (0.01,0) [-327.68|327.67] "°C" Vector__XXX
 SG_ Cell_Temperature_03 : 32|16@1- (0.01,0) [-327.68|327.67] "°C" Vector__XXX
 SG_ Cell_Temperature_02 : 16|16@1- (0.01,0) [-327.68|327.67] "°C" Vector__XXX
 SG_ Cell_Temperature_01 : 0|16@1- (0.01,0) [-327.68|327.67] "°C" Vector__XXX

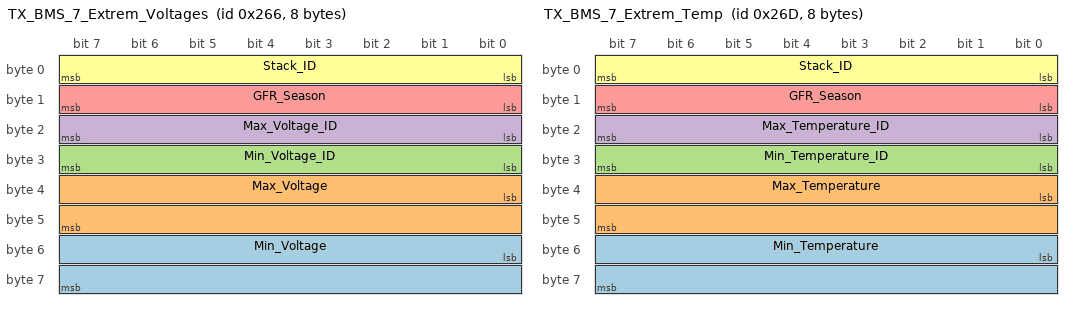
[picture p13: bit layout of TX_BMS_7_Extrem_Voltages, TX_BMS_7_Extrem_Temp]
BO_ 614 TX_BMS_7_Extrem_Voltages: 8 Vector__XXX
 SG_ Min_Voltage : 48|16@1+ (0.0001,0) [0|6.5535] "V" Vector__XXX
 SG_ Max_Voltage : 32|16@1+ (0.0001,0) [0|6.5535] "V" Vector__XXX
 SG_ Min_Voltage_ID : 24|8@1+ (1,0) [0|255] "" Vector__XXX
 SG_ Max_Voltage_ID : 16|8@1+ (1,0) [0|255] "" Vector__XXX
 SG_ GFR_Season : 8|8@1+ (1,0) [0|255] "" Vector__XXX
 SG_ Stack_ID : 0|8@1+ (1,0) [0|255] "" Vector__XXX

BO_ 621 TX_BMS_7_Extrem_Temp: 8 Vector__XXX
 SG_ Min_Temperature : 48|16@1- (0.01,0) [-327.68|327.67] "°C" Vector__XXX
 SG_ Max_Temperature : 32|16@1- (0.01,0) [-327.68|327.67] "°C" Vector__XXX
 SG_ Min_Temperature_ID : 24|8@1+ (1,0) [0|255] "" Vector__XXX
 SG_ Max_Temperature_ID : 16|8@1+ (1,0) [0|255] "" Vector__XXX
 SG_ GFR_Season : 8|8@1+ (1,0) [0|255] "" Vector__XXX
 SG_ Stack_ID : 0|8@1+ (1,0) [0|255] "" Vector__XXX

BO_ 594 TX_BMS_6_Voltage_05_08: 8 Vector__XXX
 SG_ Cell_Voltage_08 : 48|16@1+ (0.0001,0) [0|6.5535] "V" Vector__XXX
 SG_ Cell_Voltage_07 : 32|16@1+ (0.0001,0) [0|6.5535] "V" Vector__XXX
 SG_ Cell_Voltage_06 : 16|16@1+ (0.0001,0) [0|6.5535] "V" Vector__XXX
 SG_ Cell_Voltage_05 : 0|16@1+ (0.0001,0) [0|6.5535] "V" Vector__XXX

BO_ 593 TX_BMS_6_Voltage_01_04: 8 Vector__XXX
 SG_ Cell_Voltage_04 : 48|16@1+ (0.0001,0) [0|6.5535] "V" Vector__XXX
 SG_ Cell_Voltage_03 : 32|16@1+ (0.0001,0) [0|6.5535] "V" Vector__XXX
 SG_ Cell_Voltage_02 : 16|16@1+ (0.0001,0) [0|6.5535] "V" Vector__XXX
 SG_ Cell_Voltage_01 : 0|16@1+ (0.0001,0) [0|6.5535] "V" Vector__XXX

BO_ 600 TX_BMS_6_Temp_05_REF: 4 Vector__XXX
 SG_ Ref_Voltage : 16|16@1- (1,0) [0|0] "V" Vector__XXX
 SG_ Cell_Temperature_05 : 0|16@1- (0.01,0) [-327.68|327.67] "°C" Vector__XXX

BO_ 599 TX_BMS_6_Temp_01_04: 8 Vector__XXX
 SG_ Cell_Temperature_04 : 48|16@1- (0.01,0) [-327.68|327.67] "°C" Vector__XXX
 SG_ Cell_Temperature_03 : 32|16@1- (0.01,0) [-327.68|327.67] "°C" Vector__XXX
 SG_ Cell_Temperature_02 : 16|16@1- (0.01,0) [-327.68|327.67] "°C" Vector__XXX
 SG_ Cell_Temperature_01 : 0|16@1- (0.01,0) [-327.68|327.67] "°C" Vector__XXX

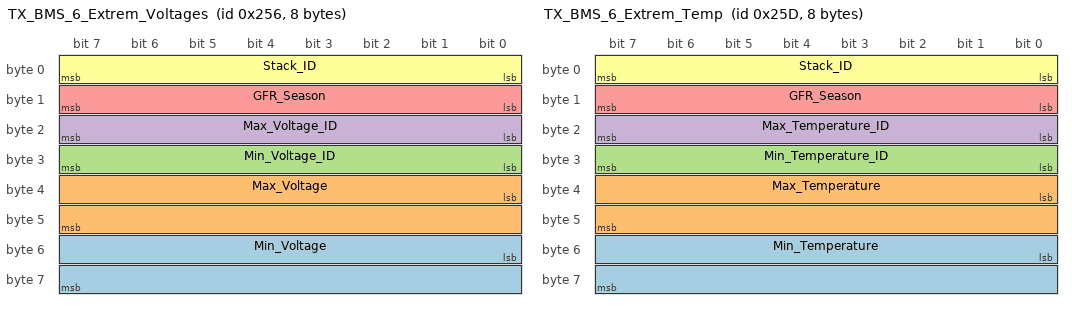
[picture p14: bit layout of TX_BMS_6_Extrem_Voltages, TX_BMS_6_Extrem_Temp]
BO_ 598 TX_BMS_6_Extrem_Voltages: 8 Vector__XXX
 SG_ Min_Voltage : 48|16@1+ (0.0001,0) [0|6.5535] "V" Vector__XXX
 SG_ Max_Voltage : 32|16@1+ (0.0001,0) [0|6.5535] "V" Vector__XXX
 SG_ Min_Voltage_ID : 24|8@1+ (1,0) [0|255] "" Vector__XXX
 SG_ Max_Voltage_ID : 16|8@1+ (1,0) [0|255] "" Vector__XXX
 SG_ GFR_Season : 8|8@1+ (1,0) [0|255] "" Vector__XXX
 SG_ Stack_ID : 0|8@1+ (1,0) [0|255] "" Vector__XXX

BO_ 605 TX_BMS_6_Extrem_Temp: 8 Vector__XXX
 SG_ Min_Temperature : 48|16@1- (0.01,0) [-327.68|327.67] "°C" Vector__XXX
 SG_ Max_Temperature : 32|16@1- (0.01,0) [-327.68|327.67] "°C" Vector__XXX
 SG_ Min_Temperature_ID : 24|8@1+ (1,0) [0|255] "" Vector__XXX
 SG_ Max_Temperature_ID : 16|8@1+ (1,0) [0|255] "" Vector__XXX
 SG_ GFR_Season : 8|8@1+ (1,0) [0|255] "" Vector__XXX
 SG_ Stack_ID : 0|8@1+ (1,0) [0|255] "" Vector__XXX

BO_ 578 TX_BMS_5_Voltage_05_08: 8 Vector__XXX
 SG_ Cell_Voltage_08 : 48|16@1+ (0.0001,0) [0|6.5535] "V" Vector__XXX
 SG_ Cell_Voltage_07 : 32|16@1+ (0.0001,0) [0|6.5535] "V" Vector__XXX
 SG_ Cell_Voltage_06 : 16|16@1+ (0.0001,0) [0|6.5535] "V" Vector__XXX
 SG_ Cell_Voltage_05 : 0|16@1+ (0.0001,0) [0|6.5535] "V" Vector__XXX

BO_ 577 TX_BMS_5_Voltage_01_04: 8 Vector__XXX
 SG_ Cell_Voltage_04 : 48|16@1+ (0.0001,0) [0|6.5535] "V" Vector__XXX
 SG_ Cell_Voltage_03 : 32|16@1+ (0.0001,0) [0|6.5535] "V" Vector__XXX
 SG_ Cell_Voltage_02 : 16|16@1+ (0.0001,0) [0|6.5535] "V" Vector__XXX
 SG_ Cell_Voltage_01 : 0|16@1+ (0.0001,0) [0|6.5535] "V" Vector__XXX

BO_ 584 TX_BMS_5_Temp_05_REF: 4 Vector__XXX
 SG_ Ref_Voltage : 16|16@1- (1,0) [0|0] "V" Vector__XXX
 SG_ Cell_Temperature_05 : 0|16@1- (0.01,0) [-327.68|327.67] "°C" Vector__XXX

BO_ 583 TX_BMS_5_Temp_01_04: 8 Vector__XXX
 SG_ Cell_Temperature_04 : 48|16@1- (0.01,0) [-327.68|327.67] "°C" Vector__XXX
 SG_ Cell_Temperature_03 : 32|16@1- (0.01,0) [-327.68|327.67] "°C" Vector__XXX
 SG_ Cell_Temperature_02 : 16|16@1- (0.01,0) [-327.68|327.67] "°C" Vector__XXX
 SG_ Cell_Temperature_01 : 0|16@1- (0.01,0) [-327.68|327.67] "°C" Vector__XXX

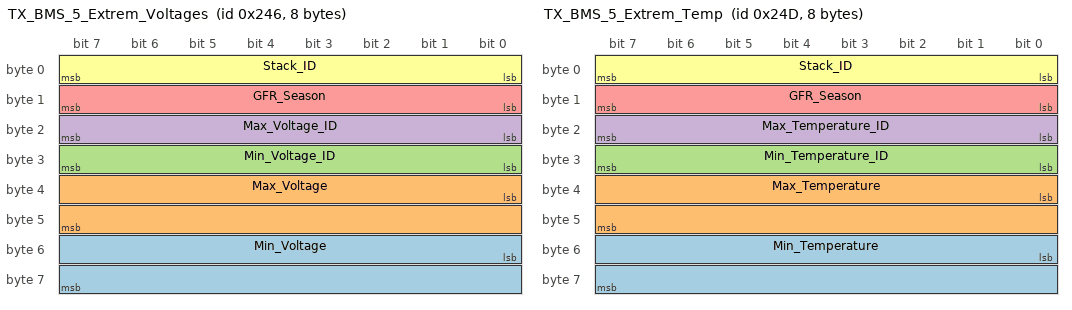
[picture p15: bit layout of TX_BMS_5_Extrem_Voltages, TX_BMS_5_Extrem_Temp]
BO_ 582 TX_BMS_5_Extrem_Voltages: 8 Vector__XXX
 SG_ Min_Voltage : 48|16@1+ (0.0001,0) [0|6.5535] "V" Vector__XXX
 SG_ Max_Voltage : 32|16@1+ (0.0001,0) [0|6.5535] "V" Vector__XXX
 SG_ Min_Voltage_ID : 24|8@1+ (1,0) [0|255] "" Vector__XXX
 SG_ Max_Voltage_ID : 16|8@1+ (1,0) [0|255] "" Vector__XXX
 SG_ GFR_Season : 8|8@1+ (1,0) [0|255] "" Vector__XXX
 SG_ Stack_ID : 0|8@1+ (1,0) [0|255] "" Vector__XXX

BO_ 589 TX_BMS_5_Extrem_Temp: 8 Vector__XXX
 SG_ Min_Temperature : 48|16@1- (0.01,0) [-327.68|327.67] "°C" Vector__XXX
 SG_ Max_Temperature : 32|16@1- (0.01,0) [-327.68|327.67] "°C" Vector__XXX
 SG_ Min_Temperature_ID : 24|8@1+ (1,0) [0|255] "" Vector__XXX
 SG_ Max_Temperature_ID : 16|8@1+ (1,0) [0|255] "" Vector__XXX
 SG_ GFR_Season : 8|8@1+ (1,0) [0|255] "" Vector__XXX
 SG_ Stack_ID : 0|8@1+ (1,0) [0|255] "" Vector__XXX

BO_ 562 TX_BMS_4_Voltage_05_08: 8 Vector__XXX
 SG_ Cell_Voltage_08 : 48|16@1+ (0.0001,0) [0|6.5535] "V" Vector__XXX
 SG_ Cell_Voltage_07 : 32|16@1+ (0.0001,0) [0|6.5535] "V" Vector__XXX
 SG_ Cell_Voltage_06 : 16|16@1+ (0.0001,0) [0|6.5535] "V" Vector__XXX
 SG_ Cell_Voltage_05 : 0|16@1+ (0.0001,0) [0|6.5535] "V" Vector__XXX

BO_ 561 TX_BMS_4_Voltage_01_04: 8 Vector__XXX
 SG_ Cell_Voltage_04 : 48|16@1+ (0.0001,0) [0|6.5535] "V" Vector__XXX
 SG_ Cell_Voltage_03 : 32|16@1+ (0.0001,0) [0|6.5535] "V" Vector__XXX
 SG_ Cell_Voltage_02 : 16|16@1+ (0.0001,0) [0|6.5535] "V" Vector__XXX
 SG_ Cell_Voltage_01 : 0|16@1+ (0.0001,0) [0|6.5535] "V" Vector__XXX

BO_ 568 TX_BMS_4_Temp_05_REF: 4 Vector__XXX
 SG_ Ref_Voltage : 16|16@1- (1,0) [0|0] "V" Vector__XXX
 SG_ Cell_Temperature_05 : 0|16@1- (0.01,0) [-327.68|327.67] "°C" Vector__XXX

BO_ 567 TX_BMS_4_Temp_01_04: 8 Vector__XXX
 SG_ Cell_Temperature_04 : 48|16@1- (0.01,0) [-327.68|327.67] "°C" Vector__XXX
 SG_ Cell_Temperature_03 : 32|16@1- (0.01,0) [-327.68|327.67] "°C" Vector__XXX
 SG_ Cell_Temperature_02 : 16|16@1- (0.01,0) [-327.68|327.67] "°C" Vector__XXX
 SG_ Cell_Temperature_01 : 0|16@1- (0.01,0) [-327.68|327.67] "°C" Vector__XXX

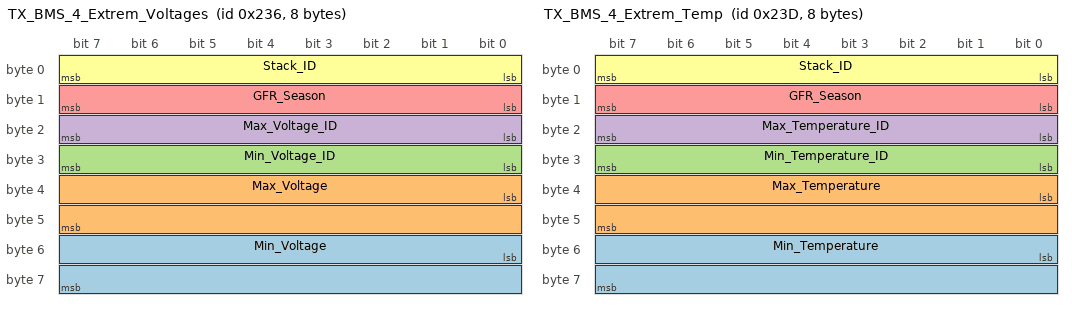
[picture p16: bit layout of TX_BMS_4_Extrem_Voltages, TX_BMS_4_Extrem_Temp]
BO_ 566 TX_BMS_4_Extrem_Voltages: 8 Vector__XXX
 SG_ Min_Voltage : 48|16@1+ (0.0001,0) [0|6.5535] "V" Vector__XXX
 SG_ Max_Voltage : 32|16@1+ (0.0001,0) [0|6.5535] "V" Vector__XXX
 SG_ Min_Voltage_ID : 24|8@1+ (1,0) [0|255] "" Vector__XXX
 SG_ Max_Voltage_ID : 16|8@1+ (1,0) [0|255] "" Vector__XXX
 SG_ GFR_Season : 8|8@1+ (1,0) [0|255] "" Vector__XXX
 SG_ Stack_ID : 0|8@1+ (1,0) [0|255] "" Vector__XXX

BO_ 573 TX_BMS_4_Extrem_Temp: 8 Vector__XXX
 SG_ Min_Temperature : 48|16@1- (0.01,0) [-327.68|327.67] "°C" Vector__XXX
 SG_ Max_Temperature : 32|16@1- (0.01,0) [-327.68|327.67] "°C" Vector__XXX
 SG_ Min_Temperature_ID : 24|8@1+ (1,0) [0|255] "" Vector__XXX
 SG_ Max_Temperature_ID : 16|8@1+ (1,0) [0|255] "" Vector__XXX
 SG_ GFR_Season : 8|8@1+ (1,0) [0|255] "" Vector__XXX
 SG_ Stack_ID : 0|8@1+ (1,0) [0|255] "" Vector__XXX

BO_ 546 TX_BMS_3_Voltage_05_08: 8 Vector__XXX
 SG_ Cell_Voltage_08 : 48|16@1+ (0.0001,0) [0|6.5535] "V" Vector__XXX
 SG_ Cell_Voltage_07 : 32|16@1+ (0.0001,0) [0|6.5535] "V" Vector__XXX
 SG_ Cell_Voltage_06 : 16|16@1+ (0.0001,0) [0|6.5535] "V" Vector__XXX
 SG_ Cell_Voltage_05 : 0|16@1+ (0.0001,0) [0|6.5535] "V" Vector__XXX

BO_ 545 TX_BMS_3_Voltage_01_04: 8 Vector__XXX
 SG_ Cell_Voltage_04 : 48|16@1+ (0.0001,0) [0|6.5535] "V" Vector__XXX
 SG_ Cell_Voltage_03 : 32|16@1+ (0.0001,0) [0|6.5535] "V" Vector__XXX
 SG_ Cell_Voltage_02 : 16|16@1+ (0.0001,0) [0|6.5535] "V" Vector__XXX
 SG_ Cell_Voltage_01 : 0|16@1+ (0.0001,0) [0|6.5535] "V" Vector__XXX

BO_ 552 TX_BMS_3_Temp_05_REF: 4 Vector__XXX
 SG_ Ref_Voltage : 16|16@1- (1,0) [0|0] "V" Vector__XXX
 SG_ Cell_Temperature_05 : 0|16@1- (0.01,0) [-327.68|327.67] "°C" Vector__XXX

BO_ 551 TX_BMS_3_Temp_01_04: 8 Vector__XXX
 SG_ Cell_Temperature_04 : 48|16@1- (0.01,0) [-327.68|327.67] "°C" Vector__XXX
 SG_ Cell_Temperature_03 : 32|16@1- (0.01,0) [-327.68|327.67] "°C" Vector__XXX
 SG_ Cell_Temperature_02 : 16|16@1- (0.01,0) [-327.68|327.67] "°C" Vector__XXX
 SG_ Cell_Temperature_01 : 0|16@1- (0.01,0) [-327.68|327.67] "°C" Vector__XXX

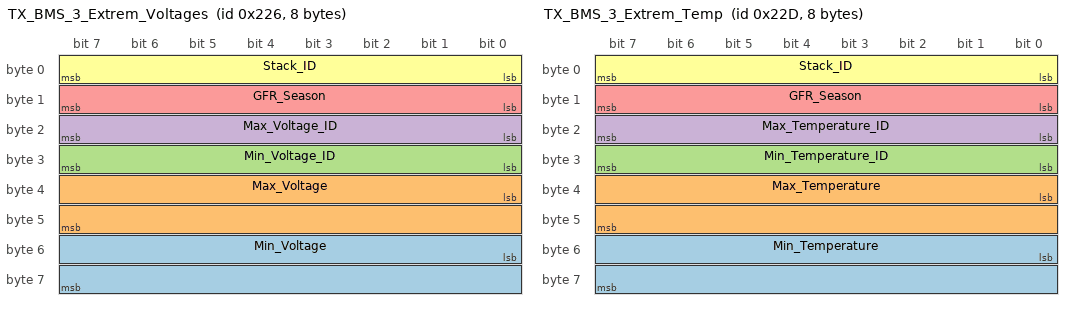
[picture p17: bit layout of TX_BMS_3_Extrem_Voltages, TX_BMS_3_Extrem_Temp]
BO_ 550 TX_BMS_3_Extrem_Voltages: 8 Vector__XXX
 SG_ Min_Voltage : 48|16@1+ (0.0001,0) [0|6.5535] "V" Vector__XXX
 SG_ Max_Voltage : 32|16@1+ (0.0001,0) [0|6.5535] "V" Vector__XXX
 SG_ Min_Voltage_ID : 24|8@1+ (1,0) [0|255] "" Vector__XXX
 SG_ Max_Voltage_ID : 16|8@1+ (1,0) [0|255] "" Vector__XXX
 SG_ GFR_Season : 8|8@1+ (1,0) [0|255] "" Vector__XXX
 SG_ Stack_ID : 0|8@1+ (1,0) [0|255] "" Vector__XXX

BO_ 557 TX_BMS_3_Extrem_Temp: 8 Vector__XXX
 SG_ Min_Temperature : 48|16@1- (0.01,0) [-327.68|327.67] "°C" Vector__XXX
 SG_ Max_Temperature : 32|16@1- (0.01,0) [-327.68|327.67] "°C" Vector__XXX
 SG_ Min_Temperature_ID : 24|8@1+ (1,0) [0|255] "" Vector__XXX
 SG_ Max_Temperature_ID : 16|8@1+ (1,0) [0|255] "" Vector__XXX
 SG_ GFR_Season : 8|8@1+ (1,0) [0|255] "" Vector__XXX
 SG_ Stack_ID : 0|8@1+ (1,0) [0|255] "" Vector__XXX

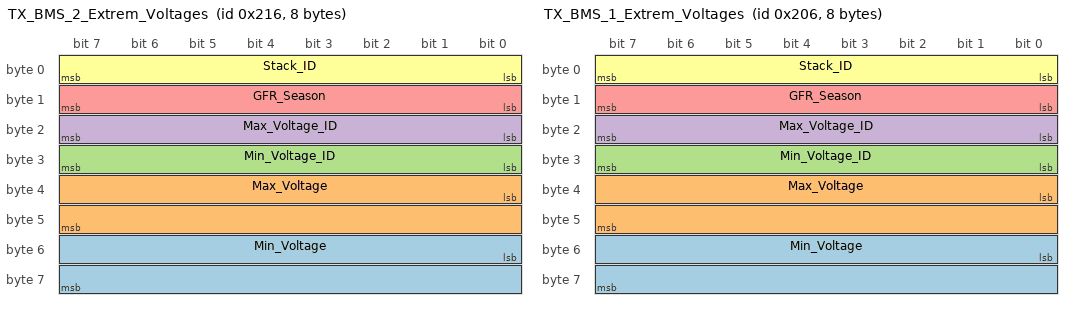
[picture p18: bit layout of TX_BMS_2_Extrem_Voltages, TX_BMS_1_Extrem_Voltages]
BO_ 534 TX_BMS_2_Extrem_Voltages: 8 Vector__XXX
 SG_ Min_Voltage : 48|16@1+ (0.0001,0) [0|6.5535] "V" Vector__XXX
 SG_ Max_Voltage : 32|16@1+ (0.0001,0) [0|6.5535] "V" Vector__XXX
 SG_ Min_Voltage_ID : 24|8@1+ (1,0) [0|255] "" Vector__XXX
 SG_ Max_Voltage_ID : 16|8@1+ (1,0) [0|255] "" Vector__XXX
 SG_ GFR_Season : 8|8@1+ (1,0) [0|255] "" Vector__XXX
 SG_ Stack_ID : 0|8@1+ (1,0) [0|255] "" Vector__XXX

BO_ 518 TX_BMS_1_Extrem_Voltages: 8 Vector__XXX
 SG_ Min_Voltage : 48|16@1+ (0.0001,0) [0|6.5535] "V" Vector__XXX
 SG_ Max_Voltage : 32|16@1+ (0.0001,0) [0|6.5535] "V" Vector__XXX
 SG_ Min_Voltage_ID : 24|8@1+ (1,0) [0|255] "" Vector__XXX
 SG_ Max_Voltage_ID : 16|8@1+ (1,0) [0|255] "" Vector__XXX
 SG_ GFR_Season : 8|8@1+ (1,0) [0|255] "" Vector__XXX
 SG_ Stack_ID : 0|8@1+ (1,0) [0|255] "" Vector__XXX

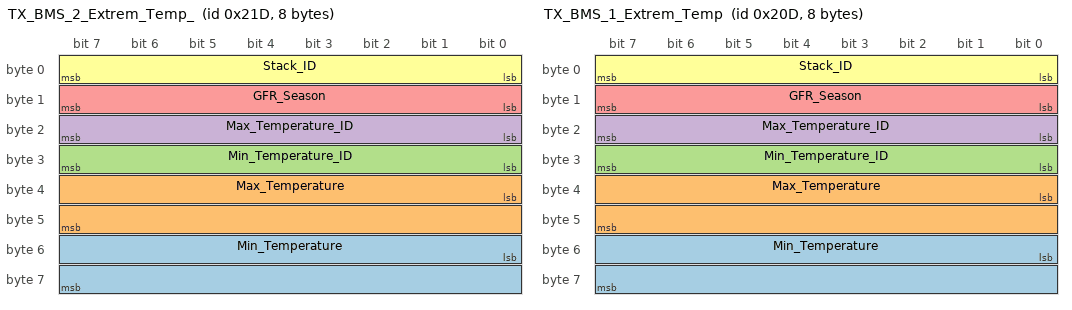
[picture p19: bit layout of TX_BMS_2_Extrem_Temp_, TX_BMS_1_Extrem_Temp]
BO_ 541 TX_BMS_2_Extrem_Temp_: 8 Vector__XXX
 SG_ Min_Temperature : 48|16@1- (0.01,0) [-327.68|327.67] "°C" Vector__XXX
 SG_ Max_Temperature : 32|16@1- (0.01,0) [-327.68|327.67] "°C" Vector__XXX
 SG_ Min_Temperature_ID : 24|8@1+ (1,0) [0|255] "" Vector__XXX
 SG_ Max_Temperature_ID : 16|8@1+ (1,0) [0|255] "" Vector__XXX
 SG_ GFR_Season : 8|8@1+ (1,0) [0|255] "" Vector__XXX
 SG_ Stack_ID : 0|8@1+ (1,0) [0|255] "" Vector__XXX

BO_ 525 TX_BMS_1_Extrem_Temp: 8 Vector__XXX
 SG_ Min_Temperature : 48|16@1- (0.01,0) [-327.68|327.67] "°C" Vector__XXX
 SG_ Max_Temperature : 32|16@1- (0.01,0) [-327.68|327.67] "°C" Vector__XXX
 SG_ Min_Temperature_ID : 24|8@1+ (1,0) [0|255] "" Vector__XXX
 SG_ Max_Temperature_ID : 16|8@1+ (1,0) [0|255] "" Vector__XXX
 SG_ GFR_Season : 8|8@1+ (1,0) [0|255] "" Vector__XXX
 SG_ Stack_ID : 0|8@1+ (1,0) [0|255] "" Vector__XXX

BO_ 530 TX_BMS_2_Voltage_05_08: 8 Vector__XXX
 SG_ Cell_Voltage_08 : 48|16@1+ (0.0001,0) [0|6.5535] "V" Vector__XXX
 SG_ Cell_Voltage_07 : 32|16@1+ (0.0001,0) [0|6.5535] "V" Vector__XXX
 SG_ Cell_Voltage_06 : 16|16@1+ (0.0001,0) [0|6.5535] "V" Vector__XXX
 SG_ Cell_Voltage_05 : 0|16@1+ (0.0001,0) [0|6.5535] "V" Vector__XXX

BO_ 529 TX_BMS_2_Voltage_01_04: 8 Vector__XXX
 SG_ Cell_Voltage_04 : 48|16@1+ (0.0001,0) [0|6.5535] "V" Vector__XXX
 SG_ Cell_Voltage_03 : 32|16@1+ (0.0001,0) [0|6.5535] "V" Vector__XXX
 SG_ Cell_Voltage_02 : 16|16@1+ (0.0001,0) [0|6.5535] "V" Vector__XXX
 SG_ Cell_Voltage_01 : 0|16@1+ (0.0001,0) [0|6.5535] "V" Vector__XXX

BO_ 536 TX_BMS_2_Temp_05_REF: 4 Vector__XXX
 SG_ Ref_Voltage : 16|16@1- (1,0) [0|0] "V" Vector__XXX
 SG_ Cell_Temperature_05 : 0|16@1- (0.01,0) [-327.68|327.67] "°C" Vector__XXX

BO_ 535 TX_BMS_2_Temp_01_04: 8 Vector__XXX
 SG_ Cell_Temperature_04 : 48|16@1- (0.01,0) [-327.68|327.67] "°C" Vector__XXX
 SG_ Cell_Temperature_03 : 32|16@1- (0.01,0) [-327.68|327.67] "°C" Vector__XXX
 SG_ Cell_Temperature_02 : 16|16@1- (0.01,0) [-327.68|327.67] "°C" Vector__XXX
 SG_ Cell_Temperature_01 : 0|16@1- (0.01,0) [-327.68|327.67] "°C" Vector__XXX

BO_ 520 TX_BMS_1_Temp_05_REF: 3 Vector__XXX
 SG_ Ref_Voltage : 16|16@1- (1,0) [0|0] "V" Vector__XXX
 SG_ Cell_Temperature_05 : 0|16@1- (0.01,0) [-327.68|327.67] "°C" Vector__XXX

BO_ 519 TX_BMS_1_Temp_01_04: 8 Vector__XXX
 SG_ Cell_Temperature_04 : 48|16@1- (0.01,0) [-327.68|327.67] "°C" Vector__XXX
 SG_ Cell_Temperature_03 : 32|16@1- (0.01,0) [-327.68|327.67] "°C" Vector__XXX
 SG_ Cell_Temperature_02 : 16|16@1- (0.01,0) [-327.68|327.67] "°C" Vector__XXX
 SG_ Cell_Temperature_01 : 0|16@1- (0.01,0) [-327.68|327.67] "°C" Vector__XXX

BO_ 514 TX_BMS_1_Voltage_05_08: 8 Vector__XXX
 SG_ Cell_Voltage_08 : 48|16@1+ (0.0001,0) [0|6.5535] "V" Vector__XXX
 SG_ Cell_Voltage_07 : 32|16@1+ (0.0001,0) [0|6.5535] "V" Vector__XXX
 SG_ Cell_Voltage_06 : 16|16@1+ (0.0001,0) [0|6.5535] "V" Vector__XXX
 SG_ Cell_Voltage_05 : 0|16@1+ (0.0001,0) [0|6.5535] "V" Vector__XXX

BO_ 513 TX_BMS_1_Voltage_01_04: 8 Vector__XXX
 SG_ Cell_Voltage_04 : 48|16@1+ (0.0001,0) [0|6.5535] "V" Vector__XXX
 SG_ Cell_Voltage_03 : 32|16@1+ (0.0001,0) [0|6.5535] "V" Vector__XXX
 SG_ Cell_Voltage_02 : 16|16@1+ (0.0001,0) [0|6.5535] "V" Vector__XXX
 SG_ Cell_Voltage_01 : 0|16@1+ (0.0001,0) [0|6.5535] "V" Vector__XXX

CM_ BO_ 3221225472 "This is a message for not used signals, created by Vector CANdb++ DBC OLE DB Provider.";
